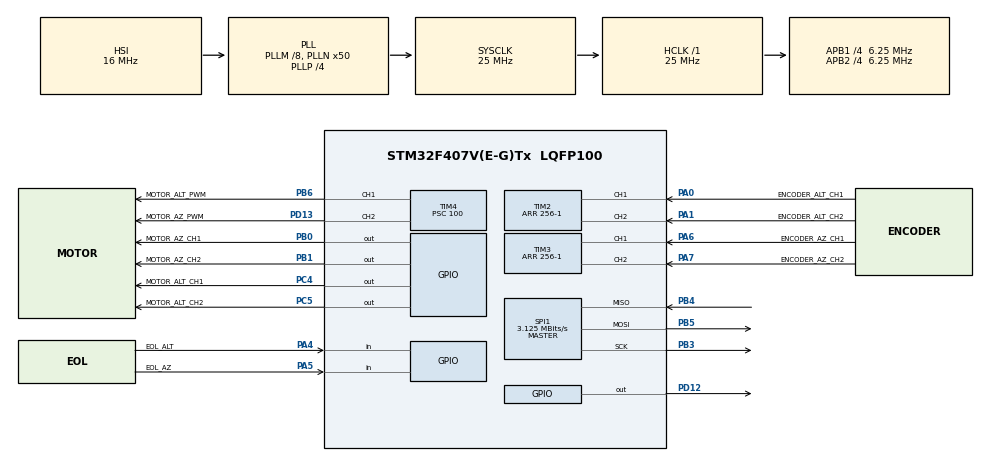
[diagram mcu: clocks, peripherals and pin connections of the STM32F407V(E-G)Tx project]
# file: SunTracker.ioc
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FREERTOS.Tasks01=mainTask,0,128,StartMainTask,Default,NULL,Dynamic,NULL,NULL
Mcu.Family=STM32F4
Mcu.Name=STM32F407V(E-G)Tx
Mcu.Package=LQFP100
NVIC.PriorityGroup=NVIC_PRIORITYGROUP_4
NVIC.TIM1_UP_TIM10_IRQn=true\:0\:0\:false\:false\:true\:false\:false
NVIC.TimeBase=TIM1_UP_TIM10_IRQn
NVIC.TimeBaseIP=TIM1
PA0-WKUP.GPIO_Label=ENCODER_ALT_CH1
PA0-WKUP.GPIO_PuPd=GPIO_PULLUP
PA0-WKUP.Signal=S_TIM2_CH1_ETR
PA1.GPIO_Label=ENCODER_ALT_CH2
PA1.GPIO_PuPd=GPIO_PULLUP
PA1.Signal=S_TIM2_CH2
PA4.GPIO_Label=EOL_ALT
PA4.Signal=GPIO_Input
PA5.GPIO_Label=EOL_AZ
PA5.Signal=GPIO_Input
PA6.GPIO_Label=ENCODER_AZ_CH1
PA6.Signal=S_TIM3_CH1
PA7.GPIO_Label=ENCODER_AZ_CH2
PA7.Signal=S_TIM3_CH2
PB0.GPIO_Label=MOTOR_AZ_CH1
PB0.Signal=GPIO_Output
PB1.GPIO_Label=MOTOR_AZ_CH2
PB1.Signal=GPIO_Output
PB3.Mode=Full_Duplex_Master
PB3.Signal=SPI1_SCK
PB4.Mode=Full_Duplex_Master
PB4.Signal=SPI1_MISO
PB5.Mode=Full_Duplex_Master
PB5.Signal=SPI1_MOSI
PB6.GPIO_Label=MOTOR_ALT_PWM
PB6.Signal=S_TIM4_CH1
PC4.GPIO_Label=MOTOR_ALT_CH1
PC4.Signal=GPIO_Output
PC5.GPIO_Label=MOTOR_ALT_CH2
PC5.Signal=GPIO_Output
PD12.Signal=GPIO_Output
PD13.GPIO_Label=MOTOR_AZ_PWM
PD13.Signal=S_TIM4_CH2
PH0-OSC_IN.Mode=HSE-External-Oscillator
PH0-OSC_IN.Signal=RCC_OSC_IN
PH1-OSC_OUT.Mode=HSE-External-Oscillator
PH1-OSC_OUT.Signal=RCC_OSC_OUT
ProjectManager.HeapSize=0x200
ProjectManager.StackSize=0x400
ProjectManager.TargetToolchain=SW4STM32
RCC.48MHZClocksFreq_Value=14285714.285714285
RCC.AHBFreq_Value=25000000
RCC.APB1CLKDivider=RCC_HCLK_DIV4
RCC.APB1Freq_Value=6250000
RCC.APB1TimFreq_Value=12500000
RCC.APB2CLKDivider=RCC_HCLK_DIV4
RCC.APB2Freq_Value=6250000
RCC.APB2TimFreq_Value=12500000
RCC.CortexFreq_Value=25000000
RCC.HCLKFreq_Value=25000000
RCC.HSE_VALUE=8000000
RCC.HSI_VALUE=16000000
RCC.LSE_VALUE=32768
RCC.PLLM=8
RCC.PLLN=50
RCC.PLLP=RCC_PLLP_DIV4
RCC.PLLQ=7
RCC.SYSCLKFreq_VALUE=25000000
RCC.SYSCLKSource=RCC_SYSCLKSOURCE_PLLCLK
RCC.VCOOutputFreq_Value=100000000
SH.S_TIM2_CH1_ETR.0=TIM2_CH1,Encoder_Interface
SH.S_TIM2_CH2.0=TIM2_CH2,Encoder_Interface
SH.S_TIM3_CH1.0=TIM3_CH1,Encoder_Interface
SH.S_TIM3_CH2.0=TIM3_CH2,Encoder_Interface
SH.S_TIM4_CH1.0=TIM4_CH1,PWM Generation1 CH1
SH.S_TIM4_CH2.0=TIM4_CH2,PWM Generation2 CH2
SPI1.CalculateBaudRate=3.125 MBits/s
SPI1.Direction=SPI_DIRECTION_2LINES
SPI1.Mode=SPI_MODE_MASTER
SPI1.VirtualType=VM_MASTER
TIM2.CounterMode=TIM_COUNTERMODE_UP
TIM2.EncoderMode=TIM_ENCODERMODE_TI12
TIM2.IC1Filter=4
TIM2.IC2Filter=4
TIM2.Period=256-1
TIM3.EncoderMode=TIM_ENCODERMODE_TI12
TIM3.IC1Filter=4
TIM3.IC2Filter=4
TIM3.Period=256-1
TIM4.Channel-PWM\ Generation1\ CH1=TIM_CHANNEL_1
TIM4.Channel-PWM\ Generation2\ CH2=TIM_CHANNEL_2
TIM4.OCMode_PWM-PWM\ Generation1\ CH1=TIM_OCMODE_PWM1
TIM4.Period=256-1
TIM4.Prescaler=100
VP_FATFS_VS_Generic.Mode=User_defined
VP_FREERTOS_VS_ENABLE.Mode=Enabled
VP_SYS_VS_tim1.Mode=TIM1
board=STM32F4DISCOVERY

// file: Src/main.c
/**
  ******************************************************************************
  * @file           : main.c
  * @brief          : Main program body
  ******************************************************************************
  * This notice applies to any and all portions of this file
  * that are not between comment pairs USER CODE BEGIN and
  * USER CODE END. Other portions of this file, whether
  * inserted by the user or by software development tools
  * are owned by their respective copyright owners.
  *
  * Copyright (c) 2018 STMicroelectronics International N.V.
  * All rights reserved.
  *
  * Redistribution and use in source and binary forms, with or without
  * modification, are permitted, provided that the following conditions are met:
  *
  * 1. Redistribution of source code must retain the above copyright notice,
  *    this list of conditions and the following disclaimer.
  * 2. Redistributions in binary form must reproduce the above copyright notice,
  *    this list of conditions and the following disclaimer in the documentation
  *    and/or other materials provided with the distribution.
  * 3. Neither the name of STMicroelectronics nor the names of other
  *    contributors to this software may be used to endorse or promote products
  *    derived from this software without specific written permission.
  * 4. This software, including modifications and/or derivative works of this
  *    software, must execute solely and exclusively on microcontroller or
  *    microprocessor devices manufactured by or for STMicroelectronics.
  * 5. Redistribution and use of this software other than as permitted under
  *    this license is void and will automatically terminate your rights under
  *    this license.
  *
  * THIS SOFTWARE IS PROVIDED BY STMICROELECTRONICS AND CONTRIBUTORS "AS IS"
  * AND ANY EXPRESS, IMPLIED OR STATUTORY WARRANTIES, INCLUDING, BUT NOT
  * LIMITED TO, THE IMPLIED WARRANTIES OF MERCHANTABILITY, FITNESS FOR A
  * PARTICULAR PURPOSE AND NON-INFRINGEMENT OF THIRD PARTY INTELLECTUAL PROPERTY
  * RIGHTS ARE DISCLAIMED TO THE FULLEST EXTENT PERMITTED BY LAW. IN NO EVENT
  * SHALL STMICROELECTRONICS OR CONTRIBUTORS BE LIABLE FOR ANY DIRECT, INDIRECT,
  * INCIDENTAL, SPECIAL, EXEMPLARY, OR CONSEQUENTIAL DAMAGES (INCLUDING, BUT NOT
  * LIMITED TO, PROCUREMENT OF SUBSTITUTE GOODS OR SERVICES; LOSS OF USE, DATA,
  * OR PROFITS; OR BUSINESS INTERRUPTION) HOWEVER CAUSED AND ON ANY THEORY OF
  * LIABILITY, WHETHER IN CONTRACT, STRICT LIABILITY, OR TORT (INCLUDING
  * NEGLIGENCE OR OTHERWISE) ARISING IN ANY WAY OUT OF THE USE OF THIS SOFTWARE,
  * EVEN IF ADVISED OF THE POSSIBILITY OF SUCH DAMAGE.
  *
  ******************************************************************************
  */
#include "main.h"
#include "stm32f4xx_hal.h"
#include "cmsis_os.h"
#include "fatfs.h"
#include "spi.h"
#include "tim.h"
#include "gpio.h"

/* USER CODE BEGIN PV */
/* Private variables ---------------------------------------------------------*/

/* USER CODE END PV */

void SystemClock_Config(void);
void MX_FREERTOS_Init(void);

/* USER CODE BEGIN PFP */
/* Private function prototypes -----------------------------------------------*/

/* USER CODE END PFP */

int main(void)
{

  /* MCU Configuration----------------------------------------------------------*/

  /* Reset of all peripherals, Initializes the Flash interface and the Systick. */
  HAL_Init();

  /* Configure the system clock */
  SystemClock_Config();

  /* Initialize all configured peripherals */
  MX_GPIO_Init();
  MX_TIM2_Init();
  MX_TIM3_Init();
  MX_TIM4_Init();
  MX_SPI1_Init();

  /* Call init function for freertos objects (in freertos.c) */
  MX_FREERTOS_Init();

  /* Start scheduler */
  osKernelStart();

  /* We should never get here as control is now taken by the scheduler */

  /* Infinite loop */
  while (1)
  {

  }

}

void SystemClock_Config(void)
{

  RCC_OscInitTypeDef RCC_OscInitStruct;
  RCC_ClkInitTypeDef RCC_ClkInitStruct;

    /**Configure the main internal regulator output voltage
    */
  __HAL_RCC_PWR_CLK_ENABLE();

  __HAL_PWR_VOLTAGESCALING_CONFIG(PWR_REGULATOR_VOLTAGE_SCALE1);

    /**Initializes the CPU, AHB and APB busses clocks
    */
  RCC_OscInitStruct.OscillatorType = RCC_OSCILLATORTYPE_HSI;
  RCC_OscInitStruct.HSIState = RCC_HSI_ON;
  RCC_OscInitStruct.HSICalibrationValue = 16;
  RCC_OscInitStruct.PLL.PLLState = RCC_PLL_ON;
  RCC_OscInitStruct.PLL.PLLSource = RCC_PLLSOURCE_HSI;
  RCC_OscInitStruct.PLL.PLLM = 8;
  RCC_OscInitStruct.PLL.PLLN = 50;
  RCC_OscInitStruct.PLL.PLLP = RCC_PLLP_DIV4;
  RCC_OscInitStruct.PLL.PLLQ = 7;
  if (HAL_RCC_OscConfig(&RCC_OscInitStruct) != HAL_OK)
  {
    _Error_Handler(__FILE__, __LINE__);
  }

    /**Initializes the CPU, AHB and APB busses clocks
    */
  RCC_ClkInitStruct.ClockType = RCC_CLOCKTYPE_HCLK|RCC_CLOCKTYPE_SYSCLK
                              |RCC_CLOCKTYPE_PCLK1|RCC_CLOCKTYPE_PCLK2;
  RCC_ClkInitStruct.SYSCLKSource = RCC_SYSCLKSOURCE_PLLCLK;
  RCC_ClkInitStruct.AHBCLKDivider = RCC_SYSCLK_DIV1;
  RCC_ClkInitStruct.APB1CLKDivider = RCC_HCLK_DIV4;
  RCC_ClkInitStruct.APB2CLKDivider = RCC_HCLK_DIV4;

  if (HAL_RCC_ClockConfig(&RCC_ClkInitStruct, FLASH_LATENCY_0) != HAL_OK)
  {
    _Error_Handler(__FILE__, __LINE__);
  }

    /**Configure the Systick interrupt time
    */
  HAL_SYSTICK_Config(HAL_RCC_GetHCLKFreq()/1000);

    /**Configure the Systick
    */
  HAL_SYSTICK_CLKSourceConfig(SYSTICK_CLKSOURCE_HCLK);

  /* SysTick_IRQn interrupt configuration */
  HAL_NVIC_SetPriority(SysTick_IRQn, 15, 0);
}

void HAL_TIM_PeriodElapsedCallback(TIM_HandleTypeDef *htim)
{
  if (htim->Instance == TIM1) {
    HAL_IncTick();
  }
}

void _Error_Handler(char *file, int line)
{
  while(1)
  {
  }
}

/************************ (C) COPYRIGHT STMicroelectronics *****END OF FILE****/

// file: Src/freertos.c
/**
  ******************************************************************************
  * File Name          : freertos.c
  * Description        : Code for freertos applications
  ******************************************************************************
  * This notice applies to any and all portions of this file
  * that are not between comment pairs USER CODE BEGIN and
  * USER CODE END. Other portions of this file, whether
  * inserted by the user or by software development tools
  * are owned by their respective copyright owners.
  *
  * Copyright (c) 2018 STMicroelectronics International N.V.
  * All rights reserved.
  *
  * Redistribution and use in source and binary forms, with or without
  * modification, are permitted, provided that the following conditions are met:
  *
  * 1. Redistribution of source code must retain the above copyright notice,
  *    this list of conditions and the following disclaimer.
  * 2. Redistributions in binary form must reproduce the above copyright notice,
  *    this list of conditions and the following disclaimer in the documentation
  *    and/or other materials provided with the distribution.
  * 3. Neither the name of STMicroelectronics nor the names of other
  *    contributors to this software may be used to endorse or promote products
  *    derived from this software without specific written permission.
  * 4. This software, including modifications and/or derivative works of this
  *    software, must execute solely and exclusively on microcontroller or
  *    microprocessor devices manufactured by or for STMicroelectronics.
  * 5. Redistribution and use of this software other than as permitted under
  *    this license is void and will automatically terminate your rights under
  *    this license.
  *
  * THIS SOFTWARE IS PROVIDED BY STMICROELECTRONICS AND CONTRIBUTORS "AS IS"
  * AND ANY EXPRESS, IMPLIED OR STATUTORY WARRANTIES, INCLUDING, BUT NOT
  * LIMITED TO, THE IMPLIED WARRANTIES OF MERCHANTABILITY, FITNESS FOR A
  * PARTICULAR PURPOSE AND NON-INFRINGEMENT OF THIRD PARTY INTELLECTUAL PROPERTY
  * RIGHTS ARE DISCLAIMED TO THE FULLEST EXTENT PERMITTED BY LAW. IN NO EVENT
  * SHALL STMICROELECTRONICS OR CONTRIBUTORS BE LIABLE FOR ANY DIRECT, INDIRECT,
  * INCIDENTAL, SPECIAL, EXEMPLARY, OR CONSEQUENTIAL DAMAGES (INCLUDING, BUT NOT
  * LIMITED TO, PROCUREMENT OF SUBSTITUTE GOODS OR SERVICES; LOSS OF USE, DATA,
  * OR PROFITS; OR BUSINESS INTERRUPTION) HOWEVER CAUSED AND ON ANY THEORY OF
  * LIABILITY, WHETHER IN CONTRACT, STRICT LIABILITY, OR TORT (INCLUDING
  * NEGLIGENCE OR OTHERWISE) ARISING IN ANY WAY OUT OF THE USE OF THIS SOFTWARE,
  * EVEN IF ADVISED OF THE POSSIBILITY OF SUCH DAMAGE.
  *
  ******************************************************************************
  */

#include "FreeRTOS.h"
#include "task.h"
#include "cmsis_os.h"

/* USER CODE BEGIN Includes */
#include "runtime/wrapper.h"
/* USER CODE END Includes */

osThreadId mainTaskHandle;

/* USER CODE BEGIN Variables */
#define ts 2000
void* taskObj;

/* USER CODE END Variables */

void StartMainTask(void const * argument);

extern void MX_FATFS_Init(void);
void MX_FREERTOS_Init(void); /* (MISRA C 2004 rule 8.1) */

/* Hook prototypes */

/* Init FreeRTOS */

void MX_FREERTOS_Init(void) {
  /* USER CODE BEGIN Init */
	taskObj = tasksCreate();
  /* USER CODE END Init */

  /* Create the thread(s) */
  /* definition and creation of mainTask */
  osThreadDef(mainTask, StartMainTask, osPriorityNormal, 0, 128);
  mainTaskHandle = osThreadCreate(osThread(mainTask), NULL);

}

/* StartMainTask function */
void StartMainTask(void const * argument)
{
  /* init code for FATFS */
  MX_FATFS_Init();

  /* USER CODE BEGIN StartMainTask */
	//uint32_t previousWakeTime = 0;
	/* Infinite loop */
	for(;;)
	{
		StepMainTask(taskObj);
		osDelay(50);
//		osDelayUntil(&previousWakeTime, ts); //Definir tiempo tarea main
		//osDelayUntil(&previous,ts)
	}
  /* USER CODE END StartMainTask */
}

/************************ (C) COPYRIGHT STMicroelectronics *****END OF FILE****/
